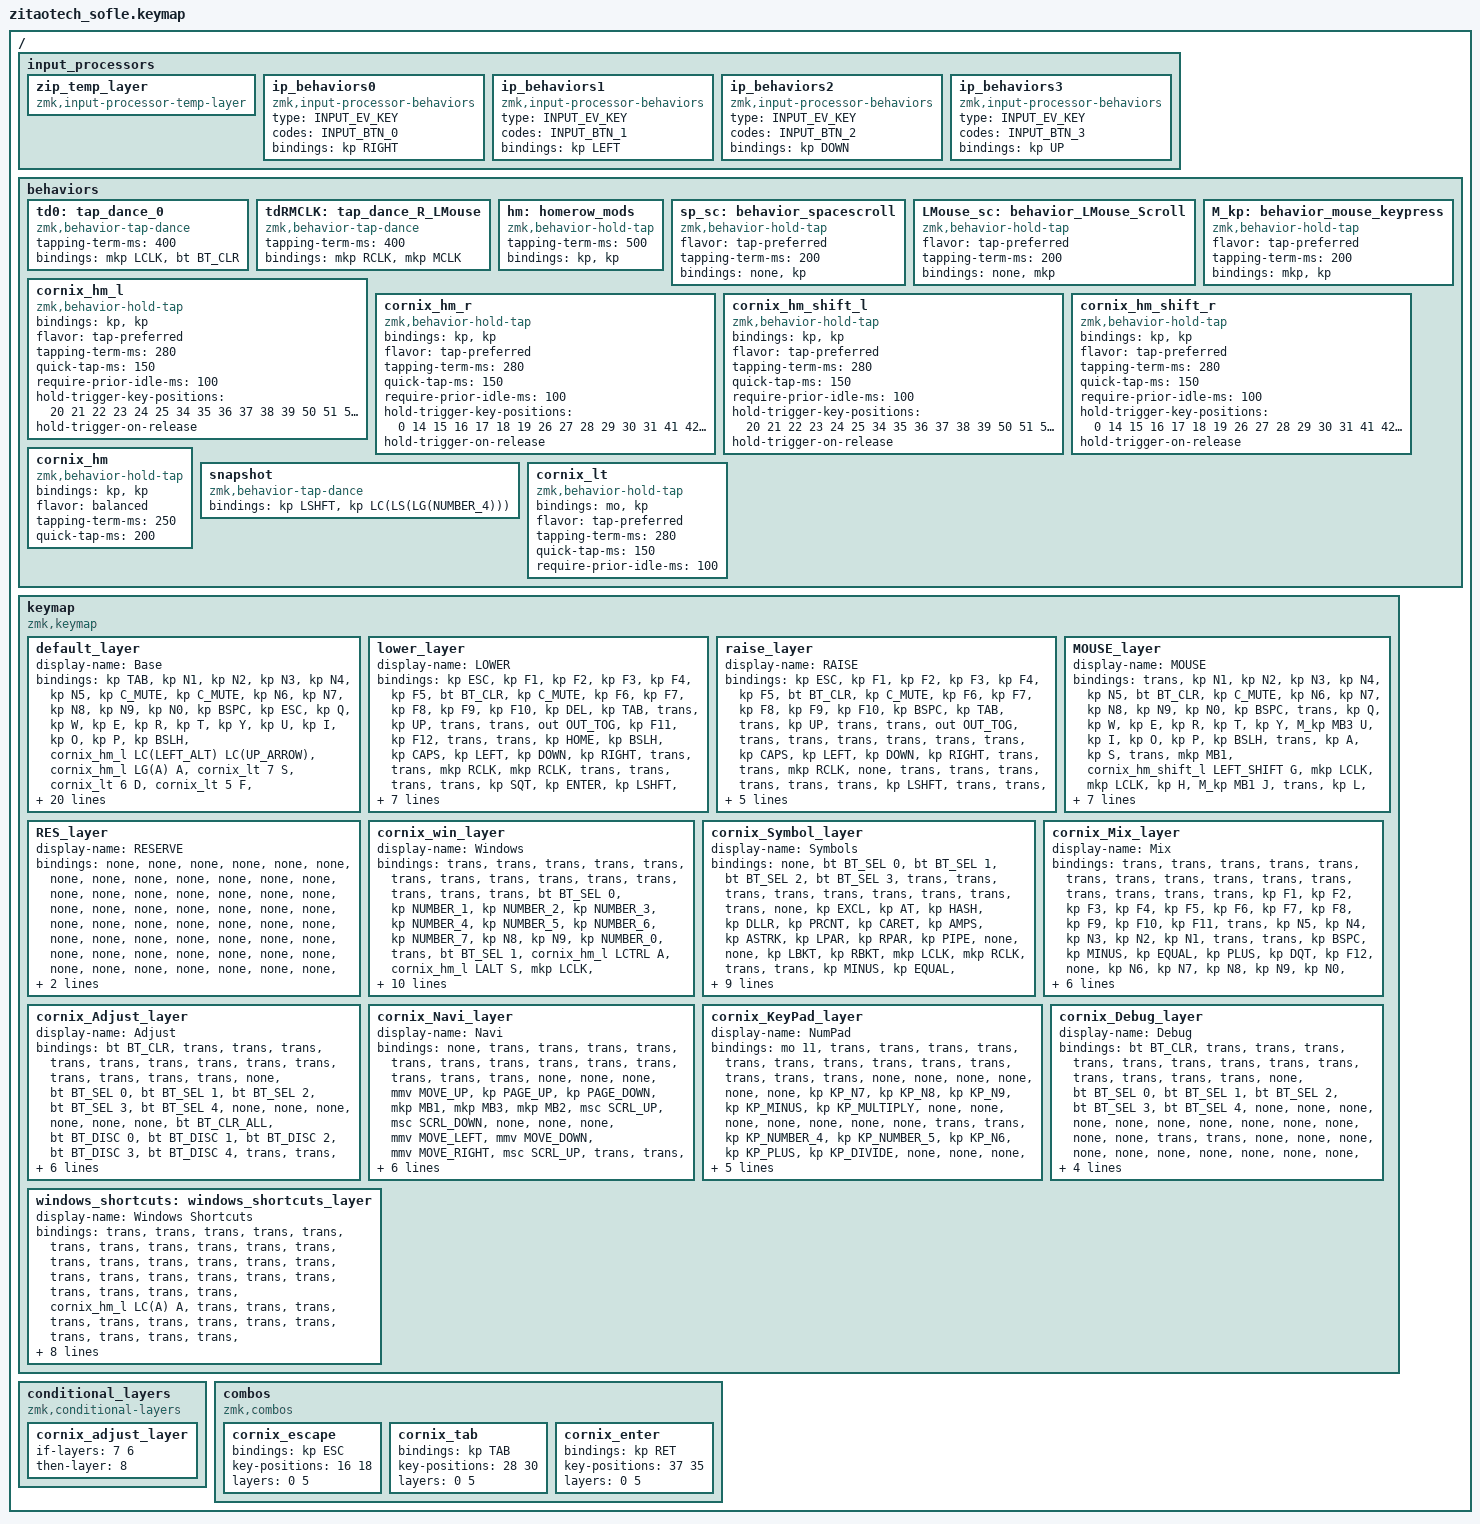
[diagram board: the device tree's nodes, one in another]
/*
 * Copyright (c) 2025 ZitaoTech
 * Copyright (c) 2020 The ZMK Contributors
 *
 * SPDX-License-Identifier: MIT
 */

#include <behaviors.dtsi>
#include <dt-bindings/zmk/keys.h>
#include <dt-bindings/zmk/bt.h>
#include <dt-bindings/zmk/outputs.h>
#include <dt-bindings/zmk/mouse.h>
#include <dt-bindings/zmk/backlight.h>
#include <dt-bindings/zmk/ext_power.h>
#include <dt-bindings/zmk/rgb.h>

#define FUNC 1
#define RES 2
#define BOT bootloader

/ {
    input_processors {

        zip_temp_layer: zip_temp_layer {
            compatible = "zmk,input-processor-temp-layer";
            #input-processor-cells = <2>;
        };

        ip_behaviors0: ip_behaviors0 {
            compatible = "zmk,input-processor-behaviors";
            #input-processor-cells = <0>;
            type = <INPUT_EV_KEY>;
            codes = <INPUT_BTN_0>;
            bindings = <&kp RIGHT>;
        };
        ip_behaviors1: ip_behaviors1 {
            compatible = "zmk,input-processor-behaviors";
            #input-processor-cells = <0>;
            type = <INPUT_EV_KEY>;
            codes = <INPUT_BTN_1>;
            bindings = <&kp LEFT>;
        };
        ip_behaviors2: ip_behaviors2 {
            compatible = "zmk,input-processor-behaviors";
            #input-processor-cells = <0>;
            type = <INPUT_EV_KEY>;
            codes = <INPUT_BTN_2>;
            bindings = <&kp DOWN>;
        };
        ip_behaviors3: ip_behaviors3 {
            compatible = "zmk,input-processor-behaviors";
            #input-processor-cells = <0>;
            type = <INPUT_EV_KEY>;
            codes = <INPUT_BTN_3>;
            bindings = <&kp UP>;
        };
    };
};

/ {
    behaviors {
        td0: tap_dance_0 {
            compatible = "zmk,behavior-tap-dance";
            #binding-cells = <0>;
            tapping-term-ms = <400>;
            bindings = <&mkp LCLK>, <&bt BT_CLR>;
        };
    };

        behaviors {
        tdRMCLK: tap_dance_R_LMouse {
            compatible = "zmk,behavior-tap-dance";
            #binding-cells = <0>;
            tapping-term-ms = <400>;
            bindings = <&mkp RCLK>, <&mkp MCLK>;
        };
    };

    behaviors {
        hm: homerow_mods {
            compatible = "zmk,behavior-hold-tap";
            #binding-cells = <2>;
            tapping-term-ms = <500>;
            bindings = <&kp &kp>;
        };
    };

    behaviors {
         sp_sc: behavior_spacescroll {
           compatible = "zmk,behavior-hold-tap";
           #binding-cells = <2>;
           flavor = "tap-preferred";     /* 单击优先 */
           tapping-term-ms = <200>;       /* 长按阈值 */
           bindings = <&none &kp>;        /* hold=none, tap=space */
        };
    };

    behaviors {
         LMouse_sc: behavior_LMouse_Scroll {
           compatible = "zmk,behavior-hold-tap";
           #binding-cells = <2>;
           flavor = "tap-preferred";     /* 单击优先 */
           tapping-term-ms = <200>;       /* 长按阈值 */
           bindings = <&none &mkp>;        /* hold=none, tap=Lmouse */
        };
    };

    behaviors {
         M_kp: behavior_mouse_keypress {
           compatible = "zmk,behavior-hold-tap";
           #binding-cells = <2>;
           flavor = "tap-preferred";     /* 单击优先 */
           tapping-term-ms = <200>;       /* 长按阈值 */
           bindings = <&mkp &kp>;        /* hold=mou key press, tap=key*/
        };
    };

    keymap {
        compatible = "zmk,keymap";

        default_layer {
            display-name = "Base";
            bindings = <
                &kp TAB  &kp N1  &kp N2  &kp N3  &kp N4  &kp N5  &kp C_MUTE  &kp C_MUTE  &kp N6  &kp N7  &kp N8  &kp N9  &kp N0  &kp BSPC
                &kp ESC  &kp Q  &kp W  &kp E  &kp R  &kp T  &kp Y  &kp U  &kp I  &kp O  &kp P  &kp BSLH
                &cornix_hm_l LC(LEFT_ALT) LC(UP_ARROW)  &cornix_hm_l LG(A) A  &cornix_lt 7 S  &cornix_lt 6 D  &cornix_lt 5 F  &cornix_hm_shift_l LEFT_SHIFT G  &mkp LCLK  &mkp LCLK  &cornix_hm_shift_r RIGHT_SHIFT H  &cornix_lt 5 J  &cornix_lt 6 K  &cornix_lt 7 L  &kp SEMICOLON  &kp SINGLE_QUOTE
                &snapshot  &cornix_hm_l LGUI Z  &cornix_hm_shift_l LG(X) X  &cornix_hm_shift_l LG(C) C  &cornix_hm_shift_l LG(V) V  &cornix_hm_shift_l LG(B) B  &kp K_MUTE  &kp PG_UP  &msc SCRL_DOWN  &kp LC(UP_ARROW)  &kp N  &kp M  &kp COMMA  &kp DOT  &kp FSLH  &kp BACKSPACE
                &kp LCTRL  &kp LEFT_ALT  &cornix_lt 10 ESCAPE  &cornix_hm LEFT_GUI TAB  &cornix_hm_shift_l LEFT_SHIFT ENTER  &cornix_hm_shift_r RIGHT_SHIFT SPACE  &cornix_hm RCTRL BACKSPACE  &cornix_lt 6 RIGHT_CONTROL  &kp EQUAL  &cornix_lt 1 GRAVE
            >;
            sensor-bindings = <&inc_dec_kp C_VOL_UP C_VOL_DN &inc_dec_kp PG_UP PG_DN>;
        };


        lower_layer {
            display-name = "LOWER";
            bindings = <
&kp ESC     &kp F1    &kp F2     &kp F3    &kp F4    &kp F5           &bt BT_CLR                   &kp C_MUTE             &kp F6    &kp F7   &kp F8     &kp F9    &kp F10    &kp DEL
&kp TAB     &trans    &kp UP     &trans    &trans    &out OUT_TOG                                                         &kp F11   &kp F12  &trans     &trans    &kp HOME   &kp BSLH
&kp CAPS    &kp LEFT  &kp DOWN   &kp RIGHT &trans    &trans           &mkp RCLK                    &mkp RCLK              &trans    &trans   &trans     &trans    &kp SQT    &kp ENTER
&kp LSHFT   &trans    &trans     &trans    &trans    &rgb_ug RGB_TOG  &trans     &trans            &bl BL_DEC  &bl BL_INC &trans    &trans   &kp LBKT   &kp RBKT  &kp UNDER  &kp PLUS
                      &BOT       &kp LGUI  &kp LALT  &kp SPACE        &mo 1                                     &mo 1     &kp SPACE &trans   &kp DOT    &BOT
            >;
            sensor-bindings = <&inc_dec_kp C_VOL_UP C_VOL_DN &inc_dec_kp UP DOWN>;
        };
        raise_layer {
            display-name = "RAISE";
            bindings = <
&kp ESC     &kp F1    &kp F2     &kp F3    &kp F4    &kp F5           &bt BT_CLR                      &kp C_MUTE       &kp F6     &kp F7    &kp F8    &kp F9    &kp F10    &kp BSPC
&kp TAB     &trans    &kp UP     &trans    &trans    &out OUT_TOG                                                      &trans     &trans    &trans    &trans    &trans     &trans
&kp CAPS    &kp LEFT  &kp DOWN   &kp RIGHT &trans    &trans           &mkp RCLK                       &none            &trans     &trans    &trans    &trans    &trans     &trans
&kp LSHFT   &trans    &trans     &trans    &trans    &rgb_ug RGB_TOG  &trans     &trans               &none  &none     &trans     &trans    &trans    &trans    &trans     &trans
                      &none      &kp LGUI  &kp LALT  &kp SPACE        &mo 1                                  &mo 1     &trans     &trans     &trans     &trans
            >;
        };
        MOUSE_layer {
            display-name = "MOUSE";
            bindings = <
&trans   &kp N1    &kp N2     &kp N3   &kp N4   &kp N5     &bt BT_CLR                       &kp C_MUTE       &kp N6     &kp N7         &kp N8    &kp N9    &kp N0   &kp BSPC
&trans   &kp Q     &kp W      &kp E    &kp R    &kp T                                                        &kp Y      &M_kp MB3 U    &kp I     &kp O     &kp P    &kp BSLH
&trans  &kp A     &kp S      &trans    &mkp MB1  &cornix_hm_shift_l LEFT_SHIFT G  &mkp LCLK  &mkp LCLK        &kp H      &M_kp MB1 J    &trans     &kp L     &kp SEMI &kp ENTER
&trans    &kp Z     &kp X      &kp C    &kp V    &kp B      &msc SCRL_DOWN   &msc SCRL_UP    &none  &none     &kp N      &M_kp MB2 M    &kp COMMA &kp DOT   &kp FSLH &kp RSHIFT
                    &kp LCTRL  &kp LGUI &trans  &trans  &mkp MB1                         &LMouse_sc 0 MB1 &tdRMCLK   &kp MINUS      &kp EQUAL    &kp GRAVE
           >;
        };
        RES_layer {
            display-name = "RESERVE";
            bindings = <
&none     &none     &none      &none    &none    &none   &none                        &none            &none   &none  &none   &none  &none  &none
&none     &none     &none      &none    &none    &none                                                 &none   &none  &none   &none  &none  &none
&none     &none     &none      &none    &none    &none   &none                        &none            &none   &none  &none   &none  &none  &none
&none     &none     &none      &none    &none    &none   &none   &none                &none  &none     &none   &none  &none   &none  &none  &none
                    &none      &none    &none    &none   &none                                         &none   &none  &none   &none  &none
            >;
        };

        cornix_win_layer {
            display-name = "Windows";
            bindings = <
                &trans  &trans  &trans  &trans  &trans  &trans  &trans  &trans  &trans  &trans  &trans  &trans  &trans  &trans
                &bt BT_SEL 0  &kp NUMBER_1  &kp NUMBER_2  &kp NUMBER_3  &kp NUMBER_4  &kp NUMBER_5  &kp NUMBER_6  &kp NUMBER_7  &kp N8  &kp N9  &kp NUMBER_0  &trans
                &bt BT_SEL 1  &cornix_hm_l LCTRL A  &cornix_hm_l LALT S  &mkp LCLK  &cornix_hm_shift_l LSHFT F  &trans  &trans  &trans  &kp LEFT  &kp DOWN  &kp UP_ARROW  &kp RIGHT  &cornix_hm_r RCTRL SEMI  &trans
                &bt BT_SEL 2  &bt BT_SEL 3  &trans  &trans  &trans  &trans  &trans  &trans  &trans  &trans  &trans  &kp HOME  &kp END  &trans  &trans  &trans
                &bt BT_SEL 4  &bt BT_CLR  &trans  &trans  &trans  &trans  &trans  &trans  &trans  &trans
            >;
            sensor-bindings = <&inc_dec_kp C_VOL_UP C_VOL_DN &inc_dec_kp PG_UP PG_DN>;
        };

        cornix_Symbol_layer {
            display-name = "Symbols";
            bindings = <
                &none  &bt BT_SEL 0 &bt BT_SEL 1 &bt BT_SEL 2 &bt BT_SEL 3 &trans  &trans  &trans  &trans  &trans  &trans  &trans  &trans  &trans
                &none  &kp EXCL  &kp AT  &kp HASH  &kp DLLR  &kp PRCNT  &kp CARET  &kp AMPS  &kp ASTRK  &kp LPAR  &kp RPAR  &kp PIPE
                &none  &none  &kp LBKT  &kp RBKT  &mkp LCLK  &mkp RCLK  &trans  &trans  &kp MINUS  &kp EQUAL  &kp LEFT_BRACKET  &kp RIGHT_BRACKET  &kp GRAVE  &kp SQT
                &none  &none  &kp RBKT  &kp RPAR  &kp PIPE  &kp BSLH  &trans  &trans  &trans  &trans  &kp UNDER  &kp PLUS  &kp LEFT_BRACE  &kp RIGHT_BRACE  &kp TILDE  &none
                &none  &none  &none  &trans  &trans  &kp TILDE  &trans  &kp GRAVE  &trans  &trans
            >;
            sensor-bindings = <&inc_dec_kp C_VOL_UP C_VOL_DN &inc_dec_kp PG_UP PG_DN>;
        };

        cornix_Mix_layer {
            display-name = "Mix";
            bindings = <
                &trans  &trans  &trans  &trans  &trans  &trans  &trans  &trans  &trans  &trans  &trans  &trans  &trans  &trans
                &trans  &kp F1  &kp F2  &kp F3  &kp F4  &kp F5  &kp F6  &kp F7  &kp F8  &kp F9  &kp F10  &kp F11
                &trans  &kp N5  &kp N4  &kp N3  &kp N2  &kp N1  &trans  &trans  &kp BSPC  &kp MINUS  &kp EQUAL  &kp PLUS  &kp DQT  &kp F12
                &none  &kp N6  &kp N7  &kp N8  &kp N9  &kp N0  &trans  &trans  &trans  &trans  &kp TAB  &kp INS  &kp HOME  &kp END  &trans  &trans
                &none  &none  &kp TAB  &trans  &kp BACKSPACE  &trans  &trans  &kp N3  &trans  &trans
            >;
            sensor-bindings = <&inc_dec_kp C_VOL_UP C_VOL_DN &inc_dec_kp PG_UP PG_DN>;
        };

        cornix_Adjust_layer {
            display-name = "Adjust";
            bindings = <
                &bt BT_CLR  &trans  &trans  &trans  &trans  &trans  &trans  &trans  &trans  &trans  &trans  &trans  &trans  &trans
                &none  &bt BT_SEL 0  &bt BT_SEL 1  &bt BT_SEL 2  &bt BT_SEL 3  &bt BT_SEL 4  &none  &none  &none  &none  &none  &none
                &bt BT_CLR_ALL  &bt BT_DISC 0  &bt BT_DISC 1  &bt BT_DISC 2  &bt BT_DISC 3  &bt BT_DISC 4  &trans  &trans  &tog 5  &to 0  &none  &none  &none  &tog 5
                &none  &none  &none  &none  &none  &none  &trans  &trans  &trans  &trans  &none  &none  &none  &none  &ext_power EP_ON  &kp CAPSLOCK
                &none  &none  &none  &none  &none  &none  &none  &kp N4  &trans  &trans
            >;
        };

        cornix_Navi_layer {
            display-name = "Navi";
            bindings = <
                &none  &trans  &trans  &trans  &trans  &trans  &trans  &trans  &trans  &trans  &trans  &trans  &trans  &trans
                &none  &none  &none  &mmv MOVE_UP  &kp PAGE_UP  &kp PAGE_DOWN  &mkp MB1  &mkp MB3  &mkp MB2  &msc SCRL_UP  &msc SCRL_DOWN  &none
                &none  &none  &mmv MOVE_LEFT  &mmv MOVE_DOWN  &mmv MOVE_RIGHT  &msc SCRL_UP  &trans  &trans  &kp LEFT  &kp DOWN  &kp UP  &kp RIGHT  &none  &none
                &none  &none  &none  &none  &none  &msc SCRL_DOWN  &trans  &trans  &trans  &trans  &trans  &trans  &none  &none  &none  &none
                &none  &none  &mo 11  &trans  &trans  &none  &none  &kp N5  &trans  &trans
            >;
        };

        cornix_KeyPad_layer {
            display-name = "NumPad";
            bindings = <
                &mo 11  &trans  &trans  &trans  &trans  &trans  &trans  &trans  &trans  &trans  &trans  &trans  &trans  &trans
                &none  &none  &none  &none  &none  &none  &kp KP_N7  &kp KP_N8  &kp KP_N9  &kp KP_MINUS  &kp KP_MULTIPLY  &none
                &none  &none  &none  &none  &none  &none  &trans  &trans  &kp KP_NUMBER_4  &kp KP_NUMBER_5  &kp KP_N6  &kp KP_PLUS  &kp KP_DIVIDE  &none
                &none  &none  &none  &none  &none  &none  &trans  &trans  &trans  &trans  &kp KP_NUMBER_1  &kp KP_NUMBER_2  &kp KP_N3  &none  &none  &none
                &none  &none  &none  &none  &mo 11  &kp KP_N0  &kp KP_DOT  &kp KP_NUMBER_0  &trans  &trans
            >;
        };

        cornix_Debug_layer {
            display-name = "Debug";
            bindings = <
                &bt BT_CLR  &trans  &trans  &trans  &trans  &trans  &trans  &trans  &trans  &trans  &trans  &trans  &trans  &trans
                &none  &bt BT_SEL 0  &bt BT_SEL 1  &bt BT_SEL 2  &bt BT_SEL 3  &bt BT_SEL 4  &none  &none  &none  &none  &none  &none
                &none  &none  &none  &none  &none  &none  &trans  &trans  &none  &none  &none  &none  &none  &none
                &none  &none  &none  &none  &none  &bootloader  &trans  &trans  &trans  &trans  &bootloader  &none  &none  &none  &none  &none
                &none  &none  &none  &none  &none  &none  &none  &kp N7  &trans  &trans
            >;
        };

        // Applied before Base for Bluetooth slot 2 by bluetooth-windows-layer.patch.
        windows_shortcuts: windows_shortcuts_layer {
            display-name = "Windows Shortcuts";
            bindings = <
                &trans  &trans  &trans  &trans  &trans  &trans  &trans  &trans  &trans  &trans  &trans  &trans  &trans  &trans
                &trans  &trans  &trans  &trans  &trans  &trans  &trans  &trans  &trans  &trans  &trans  &trans
                &trans  &cornix_hm_l LC(A) A  &trans  &trans  &trans  &trans  &trans  &trans  &trans  &trans  &trans  &trans  &trans  &trans
                &trans  &cornix_hm_l LCTRL Z  &cornix_hm_shift_l LC(X) X  &cornix_hm_shift_l LC(C) C  &cornix_hm_shift_l LC(V) V  &cornix_hm_shift_l LC(B) B  &trans  &trans  &trans  &trans  &trans  &trans  &trans  &trans  &trans  &trans
                &trans  &trans  &trans  &trans  &trans  &trans  &trans  &trans  &trans  &trans
            >;
        };
    };
};

/* Cornix keymap adaptations. */
/ {
    behaviors {
        cornix_hm_l: cornix_hm_l {
            compatible = "zmk,behavior-hold-tap";
            #binding-cells = <2>;
            bindings = <&kp>, <&kp>;

            flavor = "tap-preferred";
            tapping-term-ms = <280>;
            quick-tap-ms = <150>;
            require-prior-idle-ms = <100>;
            hold-trigger-key-positions = <20 21 22 23 24 25 34 35 36 37 38 39 50 51 52 53 54 55 59 60 61 62>;
            hold-trigger-on-release;
        };

        cornix_hm_r: cornix_hm_r {
            compatible = "zmk,behavior-hold-tap";
            #binding-cells = <2>;
            bindings = <&kp>, <&kp>;

            flavor = "tap-preferred";
            tapping-term-ms = <280>;
            quick-tap-ms = <150>;
            require-prior-idle-ms = <100>;
            hold-trigger-key-positions = <0 14 15 16 17 18 19 26 27 28 29 30 31 41 42 43 44 45 59 60 61 62>;
            hold-trigger-on-release;
        };

        cornix_hm_shift_l: cornix_hm_shift_l {
            compatible = "zmk,behavior-hold-tap";
            #binding-cells = <2>;
            bindings = <&kp>, <&kp>;

            flavor = "tap-preferred";
            tapping-term-ms = <280>;
            quick-tap-ms = <150>;
            require-prior-idle-ms = <100>;
            hold-trigger-key-positions = <20 21 22 23 24 25 34 35 36 37 38 39 50 51 52 53 54 55 59 60 61 62>;
            hold-trigger-on-release;
        };

        cornix_hm_shift_r: cornix_hm_shift_r {
            compatible = "zmk,behavior-hold-tap";
            #binding-cells = <2>;
            bindings = <&kp>, <&kp>;

            flavor = "tap-preferred";
            tapping-term-ms = <280>;
            quick-tap-ms = <150>;
            require-prior-idle-ms = <100>;
            hold-trigger-key-positions = <0 14 15 16 17 18 19 26 27 28 29 30 31 41 42 43 44 45 59 60 61 62>;

            hold-trigger-on-release;
        };

        /*
         * Non-Positional Homerow Mods
         * Used for &mm_grescm_gui behavior on left hand.
         *
         * Usage: &hm LSHFT T
         * Tap: T
         * Tap-Tap-Hold: Repeat T
         * Hold: LSHIFT
         */

        cornix_hm: cornix_hm {
            compatible = "zmk,behavior-hold-tap";
            #binding-cells = <2>;
            bindings = <&kp>, <&kp>;

            flavor = "balanced";
            tapping-term-ms = <250>;
            quick-tap-ms = <200>;
        };

        snapshot: snapshot {
            compatible = "zmk,behavior-tap-dance";
            #binding-cells = <0>;
            bindings = <&kp LSHFT>, <&kp LC(LS(LG(NUMBER_4)))>;
        };

        cornix_lt: cornix_lt {
            compatible = "zmk,behavior-hold-tap";
            #binding-cells = <2>;
            bindings = <&mo>, <&kp>;

            flavor = "tap-preferred";
            tapping-term-ms = <280>;
            quick-tap-ms = <150>;
            require-prior-idle-ms = <100>;
        };
    };

    conditional_layers {
        compatible = "zmk,conditional-layers";
        cornix_adjust_layer {
            if-layers = <7 6>;
            then-layer = <8>;
        };
    };

    combos {
        compatible = "zmk,combos";
        cornix_escape {
            bindings = <&kp ESC>;
            key-positions = <16 18>;
            layers = <0 5>;
        };

        cornix_tab {
            bindings = <&kp TAB>;
            key-positions = <28 30>;
            layers = <0 5>;
        };

        cornix_enter {
            bindings = <&kp RET>;
            key-positions = <37 35>;
            layers = <0 5>;
        };
    };
};
